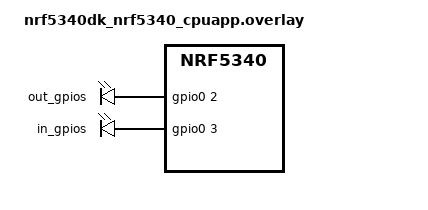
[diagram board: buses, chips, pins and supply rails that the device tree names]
/*
 * Copyright (c) 2026 Nordic Semiconductor ASA
 *
 * SPDX-License-Identifier: LicenseRef-Nordic-5-Clause
 */

/ {
	/* Test requirements:
	 * NFC antenna connected to the DK.
	 */
	test_gpios {
		compatible = "gpio-leds";

		out_gpios: out_gpios {
			gpios = <&gpio0 2 GPIO_ACTIVE_HIGH>;
		};

		in_gpios: in_gpios {
			gpios = <&gpio0 3 GPIO_ACTIVE_HIGH>;
		};
	};
};

&uicr {
	nfct-pins-as-gpios;
};

&gpiote0 {
	status = "okay";
};

&gpio0 {
	status = "okay";
};
